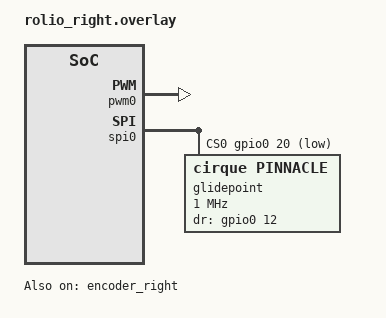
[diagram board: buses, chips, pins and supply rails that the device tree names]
#include "rolio.dtsi"

&default_transform {
    col-offset = <7>;
};

&kscan0 {
    col-gpios
        = <&gpio0 9 GPIO_ACTIVE_HIGH>
        , <&gpio1 4 GPIO_ACTIVE_HIGH>
        , <&gpio0 5 GPIO_ACTIVE_HIGH>
        , <&gpio1 9 GPIO_ACTIVE_HIGH>
        , <&gpio0 4 GPIO_ACTIVE_HIGH>
        , <&gpio0 7 GPIO_ACTIVE_HIGH>
        , <&gpio1 2 GPIO_ACTIVE_HIGH>
        ;
};

&encoder_right {
    status = "okay";
};

&pwm0 {
  status = "okay";
  pinctrl-0 = <&pwm0_default>;
  pinctrl-1 = <&pwm0_sleep>;
  pinctrl-names = "default", "sleep";
};

&spi0 {
	compatible = "nordic,nrf-spim";
    status = "okay";
    cs-gpios = <&gpio0 20 GPIO_ACTIVE_LOW>;

    glidepoint: glidepoint@0 {
        compatible = "cirque,pinnacle";
        reg = <0>;
        spi-max-frequency = <1000000>;
        status = "okay";
        dr-gpios = <&gpio0 12 (GPIO_ACTIVE_HIGH)>;
        sensitivity = "2x";
        sleep;
    };
};

// Overrides for the input-split child node
&glidepoint_split {
    device = <&glidepoint>;
};
